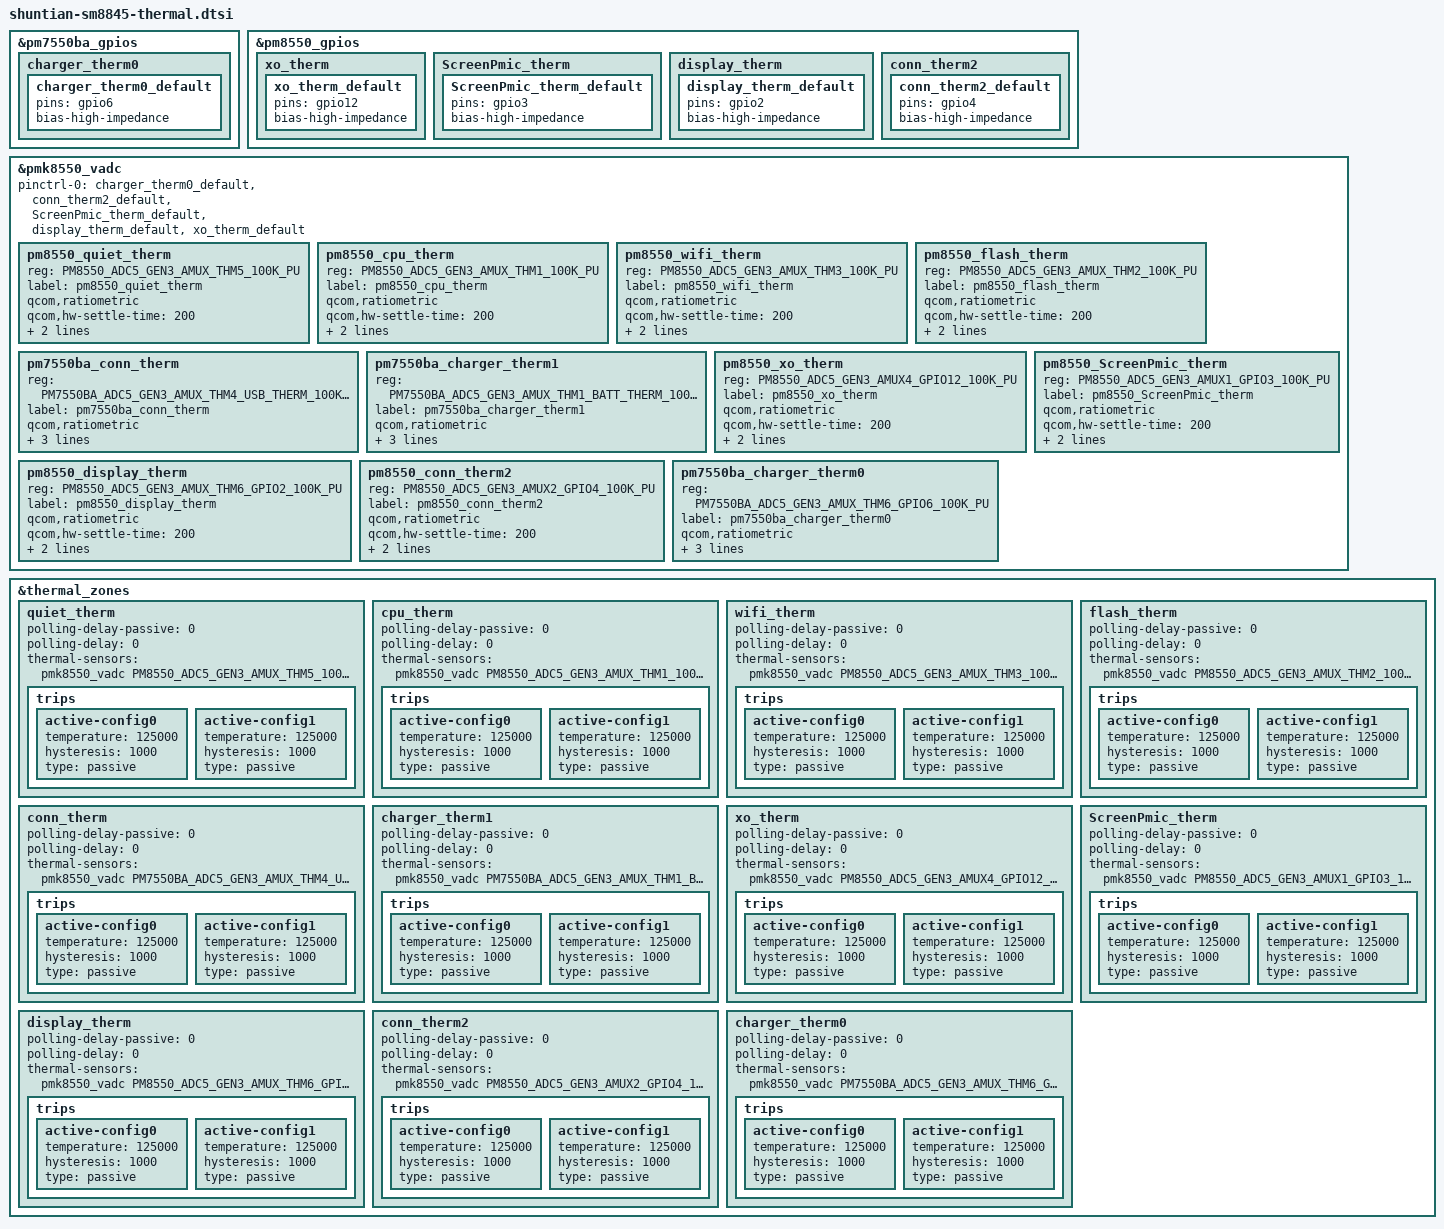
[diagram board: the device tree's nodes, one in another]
#include <dt-bindings/iio/qcom,spmi-vadc.h>
#include <dt-bindings/iio/qcom,spmi-adc5-gen3-pm7550ba.h>
#include <dt-bindings/iio/qcom,spmi-adc5-gen3-pm8550.h>

&pm7550ba_gpios {
	charger_therm0 {
		charger_therm0_default: charger_therm0_default {
			pins = "gpio6";
			bias-high-impedance;
		};
	};
};

&pm8550_gpios {
	xo_therm {
		xo_therm_default: xo_therm_default {
			pins = "gpio12";
			bias-high-impedance;
		};
	};

	ScreenPmic_therm {
		ScreenPmic_therm_default: ScreenPmic_therm_default {
			pins = "gpio3";
			bias-high-impedance;
		};
	};

	display_therm {
		display_therm_default: display_therm_default {
			pins = "gpio2";
			bias-high-impedance;
		};
	};

	conn_therm2 {
		conn_therm2_default: conn_therm2_default {
			pins = "gpio4";
			bias-high-impedance;
		};
  	};
};

&pmk8550_vadc {
	pinctrl-0 = <&charger_therm0_default>, <&conn_therm2_default>, <&ScreenPmic_therm_default>, <&display_therm_default>, <&xo_therm_default>;
	pinctrl-names = "default";

	pm8550_quiet_therm {
		reg = <PM8550_ADC5_GEN3_AMUX_THM5_100K_PU>;
		label = "pm8550_quiet_therm";
		qcom,ratiometric;
		qcom,hw-settle-time = <200>;
		qcom,pre-scaling = <1 1>;
		qcom,adc-tm-type = <1>;
	};

	pm8550_cpu_therm {
		reg = <PM8550_ADC5_GEN3_AMUX_THM1_100K_PU>;
		label = "pm8550_cpu_therm";
		qcom,ratiometric;
		qcom,hw-settle-time = <200>;
		qcom,pre-scaling = <1 1>;
		qcom,adc-tm-type = <1>;
	};

	pm8550_wifi_therm {
		reg = <PM8550_ADC5_GEN3_AMUX_THM3_100K_PU>;
		label = "pm8550_wifi_therm";
		qcom,ratiometric;
		qcom,hw-settle-time = <200>;
		qcom,pre-scaling = <1 1>;
		qcom,adc-tm-type = <1>;
	};

	pm8550_flash_therm {
		reg = <PM8550_ADC5_GEN3_AMUX_THM2_100K_PU>;
		label = "pm8550_flash_therm";
		qcom,ratiometric;
		qcom,hw-settle-time = <200>;
		qcom,pre-scaling = <1 1>;
		qcom,adc-tm-type = <1>;
	};

	pm7550ba_conn_therm {
		reg = <PM7550BA_ADC5_GEN3_AMUX_THM4_USB_THERM_100K_PU>;
		label = "pm7550ba_conn_therm";
		qcom,ratiometric;
		qcom,hw-settle-time = <200>;
		qcom,pre-scaling = <1 1>;
		qcom,adc-tm-type = <1>;
	};

	pm7550ba_charger_therm1 {
		reg = <PM7550BA_ADC5_GEN3_AMUX_THM1_BATT_THERM_100K_PU>;
		label = "pm7550ba_charger_therm1";
		qcom,ratiometric;
		qcom,hw-settle-time = <200>;
		qcom,pre-scaling = <1 1>;
		qcom,adc-tm-type = <1>;
	};

	pm8550_xo_therm {
		reg = <PM8550_ADC5_GEN3_AMUX4_GPIO12_100K_PU>;
		label = "pm8550_xo_therm";
		qcom,ratiometric;
		qcom,hw-settle-time = <200>;
		qcom,pre-scaling = <1 1>;
		qcom,adc-tm-type = <1>;
	};

	pm8550_ScreenPmic_therm {
		reg = <PM8550_ADC5_GEN3_AMUX1_GPIO3_100K_PU>;
		label = "pm8550_ScreenPmic_therm";
		qcom,ratiometric;
		qcom,hw-settle-time = <200>;
		qcom,pre-scaling = <1 1>;
		qcom,adc-tm-type = <1>;
	};

	pm8550_display_therm {
		reg = <PM8550_ADC5_GEN3_AMUX_THM6_GPIO2_100K_PU>;
		label = "pm8550_display_therm";
		qcom,ratiometric;
		qcom,hw-settle-time = <200>;
		qcom,pre-scaling = <1 1>;
		qcom,adc-tm-type = <1>;
	};

	pm8550_conn_therm2 {
		reg = <PM8550_ADC5_GEN3_AMUX2_GPIO4_100K_PU>;
		label = "pm8550_conn_therm2";
		qcom,ratiometric;
		qcom,hw-settle-time = <200>;
		qcom,pre-scaling = <1 1>;
		qcom,adc-tm-type = <1>;
	};

	pm7550ba_charger_therm0 {
		reg = <PM7550BA_ADC5_GEN3_AMUX_THM6_GPIO6_100K_PU>;
		label = "pm7550ba_charger_therm0";
		qcom,ratiometric;
		qcom,hw-settle-time = <200>;
		qcom,pre-scaling = <1 1>;
		qcom,adc-tm-type = <1>;
	};
};

&thermal_zones {
	quiet_therm {
		polling-delay-passive = <0>;
		polling-delay = <0>;
		thermal-sensors = <&pmk8550_vadc PM8550_ADC5_GEN3_AMUX_THM5_100K_PU>;

		trips {
			active-config0 {
				temperature = <125000>;
				hysteresis = <1000>;
				type = "passive";
			};

			active-config1 {
				temperature = <125000>;
				hysteresis = <1000>;
				type = "passive";
			};
		};
	};

	cpu_therm {
		polling-delay-passive = <0>;
		polling-delay = <0>;
		thermal-sensors = <&pmk8550_vadc PM8550_ADC5_GEN3_AMUX_THM1_100K_PU>;

		trips {
			active-config0 {
				temperature = <125000>;
				hysteresis = <1000>;
				type = "passive";
			};

			active-config1 {
				temperature = <125000>;
				hysteresis = <1000>;
				type = "passive";
			};
		};
	};

	wifi_therm {
		polling-delay-passive = <0>;
		polling-delay = <0>;
		thermal-sensors = <&pmk8550_vadc PM8550_ADC5_GEN3_AMUX_THM3_100K_PU>;

		trips {
			active-config0 {
				temperature = <125000>;
				hysteresis = <1000>;
				type = "passive";
			};

			active-config1 {
				temperature = <125000>;
				hysteresis = <1000>;
				type = "passive";
			};
		};
	};

	flash_therm {
		polling-delay-passive = <0>;
		polling-delay = <0>;
		thermal-sensors = <&pmk8550_vadc PM8550_ADC5_GEN3_AMUX_THM2_100K_PU>;

		trips {
			active-config0 {
				temperature = <125000>;
				hysteresis = <1000>;
				type = "passive";
			};

			active-config1 {
				temperature = <125000>;
				hysteresis = <1000>;
				type = "passive";
			};
		};
	};

	conn_therm {
		polling-delay-passive = <0>;
		polling-delay = <0>;
		thermal-sensors = <&pmk8550_vadc PM7550BA_ADC5_GEN3_AMUX_THM4_USB_THERM_100K_PU>;

		trips {
			active-config0 {
				temperature = <125000>;
				hysteresis = <1000>;
				type = "passive";
			};

			active-config1 {
				temperature = <125000>;
				hysteresis = <1000>;
				type = "passive";
			};
		};
	};

	charger_therm1 {
		polling-delay-passive = <0>;
		polling-delay = <0>;
		thermal-sensors = <&pmk8550_vadc PM7550BA_ADC5_GEN3_AMUX_THM1_BATT_THERM_100K_PU>;

		trips {
			active-config0 {
				temperature = <125000>;
				hysteresis = <1000>;
				type = "passive";
			};

			active-config1 {
				temperature = <125000>;
				hysteresis = <1000>;
				type = "passive";
			};
		};
	};

	xo_therm {
		polling-delay-passive = <0>;
		polling-delay = <0>;
		thermal-sensors = <&pmk8550_vadc PM8550_ADC5_GEN3_AMUX4_GPIO12_100K_PU>;

		trips {
			active-config0 {
				temperature = <125000>;
				hysteresis = <1000>;
				type = "passive";
			};

			active-config1 {
				temperature = <125000>;
				hysteresis = <1000>;
				type = "passive";
			};
		};
	};

	ScreenPmic_therm {
		polling-delay-passive = <0>;
		polling-delay = <0>;
		thermal-sensors = <&pmk8550_vadc PM8550_ADC5_GEN3_AMUX1_GPIO3_100K_PU>;

		trips {
			active-config0 {
				temperature = <125000>;
				hysteresis = <1000>;
				type = "passive";
			};

			active-config1 {
				temperature = <125000>;
				hysteresis = <1000>;
				type = "passive";
			};
		};
	};

	display_therm {
		polling-delay-passive = <0>;
		polling-delay = <0>;
		thermal-sensors = <&pmk8550_vadc PM8550_ADC5_GEN3_AMUX_THM6_GPIO2_100K_PU>;

		trips {
			active-config0 {
				temperature = <125000>;
				hysteresis = <1000>;
				type = "passive";
			};

			active-config1 {
				temperature = <125000>;
				hysteresis = <1000>;
				type = "passive";
			};
		};
	};

	conn_therm2 {
		polling-delay-passive = <0>;
		polling-delay = <0>;
		thermal-sensors = <&pmk8550_vadc PM8550_ADC5_GEN3_AMUX2_GPIO4_100K_PU>;

		trips {
			active-config0 {
				temperature = <125000>;
				hysteresis = <1000>;
				type = "passive";
			};

			active-config1 {
				temperature = <125000>;
				hysteresis = <1000>;
				type = "passive";
			};
		};
	};

	charger_therm0 {
		polling-delay-passive = <0>;
		polling-delay = <0>;
		thermal-sensors = <&pmk8550_vadc PM7550BA_ADC5_GEN3_AMUX_THM6_GPIO6_100K_PU>;

		trips {
			active-config0 {
				temperature = <125000>;
				hysteresis = <1000>;
				type = "passive";
			};

			active-config1 {
				temperature = <125000>;
				hysteresis = <1000>;
				type = "passive";
			};
		};
	};
};
